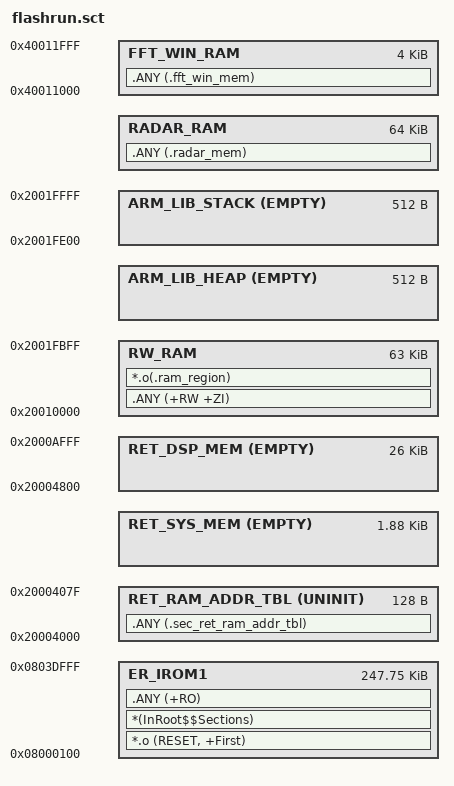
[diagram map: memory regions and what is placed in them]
#! armclang -E --target=arm-arm-none-eabi -mcpu=cortex-m0plus -xc
; *************************************************************
; *** Scatter-Loading Description File generated by uVision ***
; *************************************************************

#define STACK_SIZE        0x200
#define HEAP_SIZE         0x200

#define FLASH_BASE        0x08000100
#define FLASE_SIZE        0x0003DF00

; SRAM0 0x2000_4000 -->   0x2000_8000 (ret_ram_tbl, SYS_MEM, DSP_MEM)
#define SRAM0_16KB_BASE   0x20004000
#define SRAM0_16KB_SIZE   0x4000

; 128 = 32*4, ret_ram_tbl can have 32 items at most
#define RET_RAM_TBL_BASE  SRAM0_16KB_BASE
#define RET_RAM_TBL_SIZE  128         

#define RET_SYS_MEM_BASE  (RET_RAM_TBL_BASE + RET_RAM_TBL_SIZE)
#define RET_SYS_MEM_SIZE  (0x800 - RET_RAM_TBL_SIZE)

#define RET_DSP_MEM_BASE  0x20004800
#define RET_DSP_MEM_SIZE  0x6800

#define RAM_BASE          0x20010000
#define RAM_SIZE          0x00010000

#define RADAR_RAM_BASE    0x20020000
#define RADAR_RAM_SIZE    0x00010000

#define FFT_WIN_BASE      0x40011000


LR_IROM1 FLASH_BASE FLASE_SIZE  {    ; load region size_region
  ER_IROM1 FLASH_BASE FLASE_SIZE  {  ; load address = execution address
   *.o (RESET, +First)
   *(InRoot$$Sections)
   .ANY (+RO)
  }
  
  ; SRAM0
  RET_RAM_ADDR_TBL  RET_RAM_TBL_BASE  UNINIT RET_RAM_TBL_SIZE {
     .ANY (.sec_ret_ram_addr_tbl)
  }
  
  RET_SYS_MEM  AlignExpr(+0, 4)  EMPTY  RET_SYS_MEM_SIZE {
  }

  RET_DSP_MEM  RET_DSP_MEM_BASE  EMPTY  RET_DSP_MEM_SIZE {
  }  

  RW_RAM RAM_BASE (RAM_SIZE - HEAP_SIZE - STACK_SIZE) {
   .ANY (+RW +ZI)
   *.o(.ram_region)
  }

  ARM_LIB_HEAP AlignExpr(+0, 8) EMPTY HEAP_SIZE {  ; disable heap,if not use system heap
  }

  ARM_LIB_STACK (RAM_BASE + RAM_SIZE) EMPTY -STACK_SIZE {
  }

  RADAR_RAM AlignExpr(RADAR_RAM_BASE, 4) RADAR_RAM_SIZE { ; radar only use the memory after 0x20010000
   .ANY (.radar_mem)
  }
  FFT_WIN_RAM  FFT_WIN_BASE 0x1000 {
   .ANY (.fft_win_mem)
  }
}

